AUTOSAR XML (schema 4-2-1)
standard types defined: boolean, uint8, uint16, boolean_CompuMethod, boolean_DataConstr
package /AswDataTypes
  5 x base type, all with category=FIXED_LENGTH:
    uint8_4bit: base-type-size=4, native-declaration=uint8
    uint8_1bit: base-type-size=1, native-declaration=uint8
    AswUInt8Base: base-type-size=8, native-declaration=uint8
    AswUInt16Base: base-type-size=16, native-declaration=uint16
    AswBoolBase: base-type-size=1, native-declaration=boolean
  5 x impl type, all with category=VALUE:
    uint4: base-type=uint8_4bit
    uint1: base-type=uint8_1bit
    AswUInt8Impl: base-type=AswUInt8Base
    AswUInt16Impl: base-type=AswUInt16Base
    AswBooleanImpl: base-type=AswBoolBase
  5 x app type:
    AppUInt8: category=VALUE, implementation-data-type=AswUInt8Impl
    AppUInt16: category=VALUE, implementation-data-type=AswUInt16Impl
    AppBoolean: category=BOOLEAN, implementation-data-type=AswBooleanImpl
    AppUInt4: category=VALUE, implementation-data-type=uint4
    AppUInt1: category=VALUE, implementation-data-type=uint1
  data type mapping set DataTypeMappingSet
    data-type-maps:
      application-data-type=AppUInt8, implementation-data-type=uint8
      application-data-type=AppUInt16, implementation-data-type=uint16
      application-data-type=AppBoolean, implementation-data-type=boolean
      application-data-type=AppUInt4, implementation-data-type=uint4
      application-data-type=AppUInt1, implementation-data-type=uint1
  data type mapping set DataTypeMappingSet2
    data-type-maps:
      application-data-type=AppUInt8, implementation-data-type=AswUInt8Impl
      application-data-type=AppUInt16, implementation-data-type=AswUInt16Impl
      application-data-type=AppBoolean, implementation-data-type=AswBooleanImpl
      application-data-type=AppUInt4, implementation-data-type=uint4
      application-data-type=AppUInt1, implementation-data-type=uint1
package /AswInterfaces
  4 x sender receiver interface:
    If_CmdControl
      5 x data, all with type=AppUInt8:
        LedCmd
        TargetMode
        Cmd_AliveCnt
        PwmDuty
        Cmd_Crc8
    If_EcuStatus
      5 x data:
        ECU_State: type=AppUInt4
        ECU_AliveCnt: type=AppUInt4
        Temperature: type=AppUInt8
        SupplyVoltage: type=AppUInt16
        FaultFlags: type=AppUInt8
    If_FaultEvent
      data FaultCode: type=AppUInt8
      data FaultActive: type=AppUInt1
    If_IoOut
      data LedState: type=AppBoolean
      data PwmDuty: type=AppUInt8
package /AswComponents
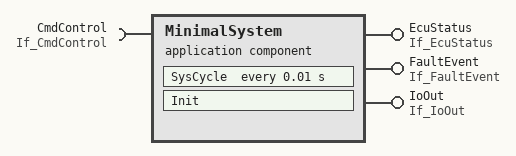
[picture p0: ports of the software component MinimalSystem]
  application sw component type MinimalSystem
    require port CmdControl: required-interface=If_CmdControl
      required-com-specs:
        data-element=LedCmd, init-value=0
        data-element=TargetMode, init-value=0
        data-element=Cmd_AliveCnt, init-value=0
        data-element=If_CmdControl/PwmDuty, init-value=0
        data-element=Cmd_Crc8, init-value=0
    provide port EcuStatus: provided-interface=If_EcuStatus
      provided-com-specs:
        data-element=ECU_State, init-value=0
        data-element=ECU_AliveCnt, init-value=0
        data-element=Temperature, init-value=0
        data-element=SupplyVoltage, init-value=0
        data-element=FaultFlags, init-value=0
    provide port FaultEvent: provided-com-specs=[{data-element=FaultCode, init-value=0}, {data-element=FaultActive, init-value=0}], provided-interface=If_FaultEvent
    provide port IoOut: provided-com-specs=[{data-element=LedState, init-value=0}, {data-element=If_IoOut/PwmDuty, init-value=0}], provided-interface=If_IoOut
    behavior MinimalSystem_IB: data-type-mapping=[DataTypeMappingSet, DataTypeMappingSet2]
      timing event SysCycleTE: start-on-event=SysCycle, offset=0, period=0.01
      runnable SysCycle: symbol=MinimalSystem_10ms
        data-read-access:
          5 x access:
            REC_CmdControl_LedCmd: accessed-variable=CmdControl.LedCmd
            REC_CmdControl_TargetMode: accessed-variable=CmdControl.TargetMode
            REC_CmdControl_Cmd_AliveCnt: accessed-variable=CmdControl.Cmd_AliveCnt
            REC_CmdControl_PwmDuty: accessed-variable=CmdControl.PwmDuty
            REC_CmdControl_Cmd_Crc8: accessed-variable=CmdControl.Cmd_Crc8
        data-write-access:
          9 x access:
            SND_EcuStatus_ECU_State: accessed-variable=EcuStatus.ECU_State
            SND_EcuStatus_ECU_AliveCnt: accessed-variable=EcuStatus.ECU_AliveCnt
            SND_EcuStatus_Temperature: accessed-variable=EcuStatus.Temperature
            SND_EcuStatus_SupplyVoltage: accessed-variable=EcuStatus.SupplyVoltage
            SND_EcuStatus_FaultFlags: accessed-variable=EcuStatus.FaultFlags
            SND_FaultEvent_FaultCode: accessed-variable=FaultEvent.FaultCode
            SND_FaultEvent_FaultActive: accessed-variable=FaultEvent.FaultActive
            SND_IoOut_LedState: accessed-variable=IoOut.LedState
            SND_IoOut_PwmDuty: accessed-variable=IoOut.PwmDuty
      runnable Init: symbol=MinimalSystem_Init
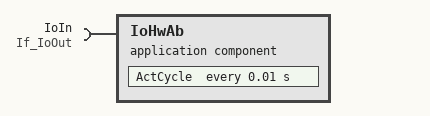
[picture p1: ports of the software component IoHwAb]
  application sw component type IoHwAb
    require port IoIn: required-com-specs=[{data-element=LedState, init-value=0}, {data-element=If_IoOut/PwmDuty, init-value=0}], required-interface=If_IoOut
    behavior IoHwAb_IB: data-type-mapping=[DataTypeMappingSet, DataTypeMappingSet2]
      timing event ActCycleTE: start-on-event=ActCycle, offset=0, period=0.01
      runnable ActCycle: symbol=IoHwAb_10ms
        data-read-access:
          access REC_IoIn_LedState: accessed-variable=IoIn.LedState
          access REC_IoIn_PwmDuty: accessed-variable=IoIn.PwmDuty
  composition sw component type COMPOSITIONTYPE  # UB:Derived from original system description
    component MinimalSystem: type=MinimalSystem
    component IoHwAb: type=IoHwAb
    connect MinimalSystem.IoOut -> IoHwAb.IoIn
